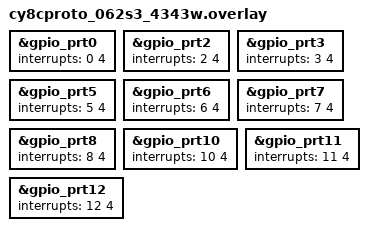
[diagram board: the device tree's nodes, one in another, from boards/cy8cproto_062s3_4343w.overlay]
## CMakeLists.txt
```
# SPDX-License-Identifier: Apache-2.0

cmake_minimum_required(VERSION 3.28.0)

find_package(Zephyr REQUIRED HINTS $ENV{ZEPHYR_BASE})
project(arm_zero_latency_irqs)

FILE(GLOB app_sources src/*.c)
target_sources(app PRIVATE ${app_sources})
```

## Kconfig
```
# Copyright (c) 2026 Nordic Semiconductor ASA
# SPDX-License-Identifier: Apache-2.0

config TEST_DIRECT_IRQ_MAX
	int "Max offset of direct IRQ used for the test"
	default NUM_IRQS

source "Kconfig.zephyr"
```

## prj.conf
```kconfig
CONFIG_ZTEST=y
CONFIG_DYNAMIC_INTERRUPTS=y
CONFIG_DYNAMIC_DIRECT_INTERRUPTS=y
CONFIG_ZERO_LATENCY_IRQS=y
```

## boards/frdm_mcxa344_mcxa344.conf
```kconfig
# SPDX-FileCopyrightText: Copyright 2026 NXP
# SPDX-License-Identifier: Apache-2.0

# The dynamic direct test uses TEST_DIRECT_IRQ_MAX - 1; its default selects
# reserved IRQ 121 on MCXA344, so can't use this default one.
# If use IRQ 120 for dynamic direct test, then zero-latency test
# will downward scan, to use the IRQ 119 (RTC), but the RTC time invalid
# interrupt is pending by default (TIF=1, TIIE=1, TCE=0), this will
# results in endless interrupt.
# Here use SMARTDMA (IRQ 108) instead for dynamic direct test. And leave
# IRQ 120 for zero latency test.
CONFIG_TEST_DIRECT_IRQ_MAX=109
```

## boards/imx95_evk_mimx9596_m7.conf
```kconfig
# Copyright 2026 NXP
# SPDX-License-Identifier: Apache-2.0
# On imx95_evk/mimx9596/m7, IRQ 233 = IRQSTEER_9_IRQn (interrupt aggregator)
# which cannot be software-triggered. Use IRQ 204 (Reserved220_IRQn) instead.
CONFIG_TEST_DIRECT_IRQ_MAX=205
```

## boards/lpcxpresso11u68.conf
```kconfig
# IRQ 39 is not software-pendable on LPC11U68.
# Use an unused first-level NVIC IRQ below the reserved high-vector range.
CONFIG_TEST_DIRECT_IRQ_MAX=32
```

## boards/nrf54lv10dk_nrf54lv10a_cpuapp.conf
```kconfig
CONFIG_TEST_DIRECT_IRQ_MAX=200
```

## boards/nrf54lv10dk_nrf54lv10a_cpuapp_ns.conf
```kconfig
CONFIG_TEST_DIRECT_IRQ_MAX=270
```

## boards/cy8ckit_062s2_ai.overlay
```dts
/*
 * Copyright (c) 2024 Arrow Electronics.
 *
 * SPDX-License-Identifier: Apache-2.0
 */

/* Changed default interrupts priority for GPIO to 4 */
&gpio_prt2 {
	interrupts = <2 4>;
};

&gpio_prt3 {
	interrupts = <3 4>;
};

&gpio_prt4 {
	interrupts = <4 4>;
};

&gpio_prt5 {
	interrupts = <5 4>;
};

&gpio_prt10 {
	interrupts = <10 4>;
};
```

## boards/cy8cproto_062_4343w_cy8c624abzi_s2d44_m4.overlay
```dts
/*
 * Copyright (c) 2024 Cypress Semiconductor Corporation.
 * SPDX-License-Identifier: Apache-2.0
 */

/* Changed default interrupts priority for GPIO to 4 */
&gpio_prt0 {
	interrupts = <0 4>;
};

&gpio_prt2 {
	interrupts = <2 4>;
};

&gpio_prt3 {
	interrupts = <3 4>;
};

&gpio_prt5 {
	interrupts = <5 4>;
};

&gpio_prt6 {
	interrupts = <6 4>;
};

&gpio_prt9 {
	interrupts = <9 4>;
};

&gpio_prt12 {
	interrupts = <12 4>;
};

&gpio_prt13 {
	interrupts = <13 4>;
};
```

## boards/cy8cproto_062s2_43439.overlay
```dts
/*
 * SPDX-FileCopyrightText: Copyright (c) 2026 Infineon Technologies AG,
 * SPDX-FileCopyrightText: or an affiliate of Infineon Technologies AG. All rights reserved.
 *
 * SPDX-License-Identifier: Apache-2.0
 */

/* Changed default interrupts priority for GPIO to 4 */
&gpio_prt0 {
	interrupts = <0 4>;
};

&gpio_prt2 {
	interrupts = <2 4>;
};

&gpio_prt3 {
	interrupts = <3 4>;
};

&gpio_prt5 {
	interrupts = <5 4>;
};

&gpio_prt6 {
	interrupts = <6 4>;
};

&gpio_prt9 {
	interrupts = <9 4>;
};

&gpio_prt12 {
	interrupts = <12 4>;
};

&gpio_prt13 {
	interrupts = <13 4>;
};
```

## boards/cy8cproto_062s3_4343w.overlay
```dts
/*
 * SPDX-FileCopyrightText: Copyright The Zephyr Project Contributors
 * SPDX-License-Identifier: Apache-2.0
 */

/* Changed default interrupts priority for GPIO to 4 */
&gpio_prt0 {
	interrupts = <0 4>;
};

&gpio_prt2 {
	interrupts = <2 4>;
};

&gpio_prt3 {
	interrupts = <3 4>;
};

&gpio_prt5 {
	interrupts = <5 4>;
};

&gpio_prt6 {
	interrupts = <6 4>;
};

&gpio_prt7 {
	interrupts = <7 4>;
};

&gpio_prt8 {
	interrupts = <8 4>;
};

&gpio_prt10 {
	interrupts = <10 4>;
};

&gpio_prt11 {
	interrupts = <11 4>;
};

&gpio_prt12 {
	interrupts = <12 4>;
};
```

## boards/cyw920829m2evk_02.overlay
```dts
/*
 * Copyright (c) 2024 Cypress Semiconductor Corporation.
 * SPDX-License-Identifier: Apache-2.0
 */

/* Changed default interrupts priority for GPIO to 4 */
&gpio_prt0 {
	interrupts = <0 4>;
};

&gpio_prt1 {
	interrupts = <1 4>;
};

&gpio_prt3 {
	interrupts = <3 4>;
};

&gpio_prt5 {
	interrupts = <5 4>;
};
```

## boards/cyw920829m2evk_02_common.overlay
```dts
/*
 * SPDX-FileCopyrightText: <text>Copyright (c) 2026 Infineon Technologies AG,
 * or an affiliate of Infineon Technologies AG. All rights reserved.</text>
 *
 * SPDX-License-Identifier: Apache-2.0
 */

/* Changed default interrupts priority for GPIO to 4 */
&gpio_prt0 {
	interrupts = <0 4>;
};

&gpio_prt1 {
	interrupts = <1 4>;
};

&gpio_prt3 {
	interrupts = <3 4>;
};

&gpio_prt5 {
	interrupts = <5 4>;
};
```

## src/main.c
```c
/*
 * Copyright (c) 2019 Nordic Semiconductor ASA
 *
 * SPDX-License-Identifier: Apache-2.0
 */

#include <zephyr/ztest.h>

ZTEST_SUITE(arm_irq_advanced_features, NULL, NULL, NULL, NULL, NULL);
```

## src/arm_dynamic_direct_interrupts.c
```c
/*
 * Copyright (c) 2019 Nordic Semiconductor ASA.
 *
 * SPDX-License-Identifier: Apache-2.0
 */

#include <zephyr/ztest.h>
#include <zephyr/arch/cpu.h>
#include <cmsis_core.h>
#include <zephyr/sys/barrier.h>

/* Offset for the Direct interrupt used in this test. */
#ifdef CONFIG_2ND_LVL_ISR_TBL_OFFSET
#define DIRECT_ISR_OFFSET (CONFIG_2ND_LVL_ISR_TBL_OFFSET - 1)
#else
#define DIRECT_ISR_OFFSET (CONFIG_TEST_DIRECT_IRQ_MAX - 1)
#endif

static volatile int test_flag;

void arm_direct_isr_handler_0(const void *args)
{
	ARG_UNUSED(args);

	test_flag = 1;
}

void arm_direct_isr_handler_1(const void *args)
{
	ARG_UNUSED(args);

	test_flag = 2;
}

/**
 * @brief Test the ARM Dynamic Direct Interrupts functionality.
 * @ingroup kernel_arch_interrupt_tests
 */
ZTEST(arm_irq_advanced_features, test_arm_dynamic_direct_interrupts)
{
	int post_flag = 0;

	/* Place the dynamic interrupt dispatcher (with no rescheduling)
	 * in the ROM ISR table.
	 */
	ARM_IRQ_DIRECT_DYNAMIC_CONNECT(DIRECT_ISR_OFFSET, 0, 0, no_reschedule);

	/* Ensure the IRQ is disabled before enabling it at run time */
	irq_disable(DIRECT_ISR_OFFSET);

	/* Attach the ISR handler at run time. */
	irq_connect_dynamic(DIRECT_ISR_OFFSET, 0 /* highest priority */, arm_direct_isr_handler_0,
			    NULL, 0);

	/* Enable and pend the interrupt */
	irq_enable(DIRECT_ISR_OFFSET);
	NVIC_SetPendingIRQ(DIRECT_ISR_OFFSET);

	/*
	 * Instruction barriers to make sure the NVIC IRQ is
	 * set to pending state before 'test_flag' is checked.
	 */
	barrier_dsync_fence_full();
	barrier_isync_fence_full();

	/* Confirm test flag is set by the dynamic direct ISR handler. */
	post_flag = test_flag;
	zassert_true(post_flag == 1, "Test flag not set by ISR0\n");

	post_flag = 0;
	irq_disable(DIRECT_ISR_OFFSET);

	/* Attach an alternative ISR handler at run-time. */
	irq_connect_dynamic(DIRECT_ISR_OFFSET, 0 /* highest priority */, arm_direct_isr_handler_1,
			    NULL, 0);

	/* Enable and pend the interrupt */
	irq_enable(DIRECT_ISR_OFFSET);
	NVIC_SetPendingIRQ(DIRECT_ISR_OFFSET);

	/*
	 * Instruction barriers to make sure the NVIC IRQ is
	 * set to pending state before 'test_flag' is checked.
	 */
	barrier_dsync_fence_full();
	barrier_isync_fence_full();

	/* Confirm test flag is set by the dynamic direct ISR handler. */
	post_flag = test_flag;
	zassert_true(post_flag == 2, "Test flag not set by ISR1\n");
}
```

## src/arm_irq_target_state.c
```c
/*
 * Copyright (c) 2020 Nordic Semiconductor ASA.
 *
 * SPDX-License-Identifier: Apache-2.0
 */

#include <zephyr/ztest.h>
#include <zephyr/interrupt_util.h>
#include <zephyr/arch/cpu.h>
#include <cmsis_core.h>

#if defined(CONFIG_ARM_SECURE_FIRMWARE) && defined(CONFIG_ARMV7_M_ARMV8_M_MAINLINE)
#if CONFIG_2ND_LVL_ISR_TBL_OFFSET > 0
#define TEST_1ST_LEVEL_INTERRUPTS_MAX CONFIG_2ND_LVL_ISR_TBL_OFFSET
#else
#define TEST_1ST_LEVEL_INTERRUPTS_MAX CONFIG_NUM_IRQS
#endif

extern irq_target_state_t irq_target_state_set(unsigned int irq, irq_target_state_t target_state);
extern int irq_target_state_is_secure(unsigned int irq);

/**
 * @brief Test the ARM IRQ target state functionality.
 * @ingroup kernel_arch_interrupt_tests
 */
ZTEST(arm_irq_advanced_features, test_arm_irq_target_state)
{
	/* Determine an NVIC IRQ line that is implemented
	 * but not currently in use.
	 */
	int i = get_available_nvic_line(TEST_1ST_LEVEL_INTERRUPTS_MAX);

	TC_PRINT("Available IRQ line: %u\n", i);

	/* Set the available IRQ line to Secure and check the result. */
	irq_target_state_t result_state = irq_target_state_set(i, IRQ_TARGET_STATE_SECURE);

	zassert_equal(result_state, IRQ_TARGET_STATE_SECURE, "Target state not set to Secure\n");

	zassert_equal(irq_target_state_is_secure(i), 1, "Target state not set to Secure\n");

	/* Set the available IRQ line to Secure and check the result. */
	result_state = irq_target_state_set(i, IRQ_TARGET_STATE_NON_SECURE);

	zassert_equal(result_state, IRQ_TARGET_STATE_NON_SECURE,
		      "Target state not set to Secure\n");
	zassert_equal(irq_target_state_is_secure(i), 0, "Target state not set to Non-Secure\n");

	result_state = irq_target_state_set(i, IRQ_TARGET_STATE_SECURE);

	zassert_equal(result_state, IRQ_TARGET_STATE_SECURE, "Target state not set to Secure\n");

	zassert_equal(irq_target_state_is_secure(i), 1, "Target state not set to Secure\n");
}
#else
ZTEST(arm_irq_advanced_features, test_arm_irq_target_state)
{
	TC_PRINT("Skipped (TrustZone-M-enabled Cortex-M Mainline only)\n");
}
#endif /* CONFIG_ZERO_LATENCY_IRQS */
```

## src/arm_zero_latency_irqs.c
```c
/*
 * Copyright (c) 2019 Nordic Semiconductor ASA.
 *
 * SPDX-License-Identifier: Apache-2.0
 */

#include <zephyr/ztest.h>
#include <zephyr/arch/cpu.h>
#include <cmsis_core.h>
#include <zephyr/interrupt_util.h>
#include <zephyr/sys/barrier.h>

#if CONFIG_2ND_LVL_ISR_TBL_OFFSET > 0
#define TEST_1ST_LEVEL_INTERRUPTS_MAX CONFIG_2ND_LVL_ISR_TBL_OFFSET
#else
#define TEST_1ST_LEVEL_INTERRUPTS_MAX CONFIG_NUM_IRQS
#endif

static volatile int test_flag;

void arm_zero_latency_isr_handler(const void *args)
{
	ARG_UNUSED(args);

	test_flag = 1;
}

/**
 * @brief Test ARM Zero latency Interrupt functionality.
 * @ingroup kernel_arch_interrupt_tests
 */
ZTEST(arm_irq_advanced_features, test_arm_zero_latency_irqs)
{

	if (!IS_ENABLED(CONFIG_ZERO_LATENCY_IRQS)) {
		TC_PRINT("Skipped (Cortex-M Mainline only)\n");

		return;
	}

	/* Determine an NVIC IRQ line that is not currently in use. */
	int i, key;
	int init_flag, post_flag;

	init_flag = test_flag;

	zassert_false(init_flag, "Test flag not initialized to zero\n");

	i = get_available_nvic_line(TEST_1ST_LEVEL_INTERRUPTS_MAX);
	TC_PRINT("Available IRQ line: %u\n", i);

	/* Configure the available IRQ line as zero-latency. */

	arch_irq_connect_dynamic(i, 0 /* Unused */, arm_zero_latency_isr_handler, NULL,
				 IRQ_ZERO_LATENCY);

	NVIC_EnableIRQ(i);

	/* Lock interrupts */
	key = irq_lock();

	/* Set the zero-latency IRQ to pending state. */
	NVIC_SetPendingIRQ(i);

	/*
	 * Instruction barriers to make sure the NVIC IRQ is
	 * set to pending state before 'test_flag' is checked.
	 */
	barrier_dsync_fence_full();
	barrier_isync_fence_full();

	/* Confirm test flag is set by the zero-latency ISR handler. */
	post_flag = test_flag;
	zassert_true(post_flag == 1, "Test flag not set by ISR\n");

	irq_unlock(key);
}
```
